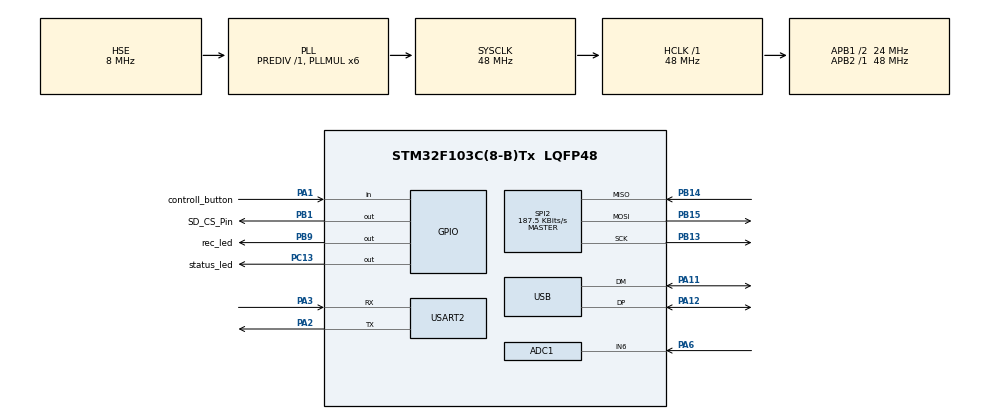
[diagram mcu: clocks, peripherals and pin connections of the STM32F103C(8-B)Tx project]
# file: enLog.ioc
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ADC1.Channel-5\#ChannelRegularConversion=ADC_CHANNEL_6
ADC1.NbrOfConversionFlag=1
ADC1.Rank-5\#ChannelRegularConversion=1
ADC1.SamplingTime-5\#ChannelRegularConversion=ADC_SAMPLETIME_1CYCLE_5
ADC1.master=1
Mcu.Family=STM32F1
Mcu.Name=STM32F103C(8-B)Tx
Mcu.Package=LQFP48
NVIC.PriorityGroup=NVIC_PRIORITYGROUP_4
NVIC.USB_LP_CAN1_RX0_IRQn=true\:0\:0\:false\:false\:true\:false\:true
PA1.GPIO_Label=controll_button
PA1.GPIO_PuPd=GPIO_PULLUP
PA1.Signal=GPIO_Input
PA11.Mode=Device
PA11.Signal=USB_DM
PA12.Mode=Device
PA12.Signal=USB_DP
PA13.Mode=Serial_Wire
PA13.Signal=SYS_JTMS-SWDIO
PA14.Mode=Serial_Wire
PA14.Signal=SYS_JTCK-SWCLK
PA2.Mode=Asynchronous
PA2.Signal=USART2_TX
PA3.Mode=Asynchronous
PA3.Signal=USART2_RX
PA6.Signal=ADCx_IN6
PB1.GPIO_Label=SD_CS_Pin
PB1.Signal=GPIO_Output
PB13.Mode=Full_Duplex_Master
PB13.Signal=SPI2_SCK
PB14.Mode=Full_Duplex_Master
PB14.Signal=SPI2_MISO
PB15.Mode=Full_Duplex_Master
PB15.Signal=SPI2_MOSI
PB9.GPIO_Label=rec_led
PB9.Signal=GPIO_Output
PC13-TAMPER-RTC.GPIO_Label=status_led
PC13-TAMPER-RTC.Signal=GPIO_Output
PC14-OSC32_IN.Mode=LSE-External-Oscillator
PC14-OSC32_IN.Signal=RCC_OSC32_IN
PC15-OSC32_OUT.Mode=LSE-External-Oscillator
PC15-OSC32_OUT.Signal=RCC_OSC32_OUT
PD0-OSC_IN.Mode=HSE-External-Oscillator
PD0-OSC_IN.Signal=RCC_OSC_IN
PD1-OSC_OUT.Mode=HSE-External-Oscillator
PD1-OSC_OUT.Signal=RCC_OSC_OUT
ProjectManager.HeapSize=0x200
ProjectManager.StackSize=0x400
ProjectManager.TargetToolchain=STM32CubeIDE
RCC.ADCPresc=RCC_ADCPCLK2_DIV4
RCC.AHBFreq_Value=48000000
RCC.APB1CLKDivider=RCC_HCLK_DIV2
RCC.APB1Freq_Value=24000000
RCC.APB1TimFreq_Value=48000000
RCC.APB2Freq_Value=48000000
RCC.APB2TimFreq_Value=48000000
RCC.HCLKFreq_Value=48000000
RCC.PLLMUL=RCC_PLL_MUL6
RCC.RTCClockSelection=RCC_RTCCLKSOURCE_LSE
RCC.SYSCLKFreq_VALUE=48000000
RCC.SYSCLKSource=RCC_SYSCLKSOURCE_PLLCLK
RCC.USBFreq_Value=48000000
SH.ADCx_IN6.0=ADC1_IN6,IN6
SPI2.BaudRatePrescaler=SPI_BAUDRATEPRESCALER_128
SPI2.CalculateBaudRate=187.5 KBits/s
SPI2.Direction=SPI_DIRECTION_2LINES
SPI2.Mode=SPI_MODE_MASTER
SPI2.VirtualType=VM_MASTER
USART2.VirtualMode=VM_ASYNC
USB_DEVICE.CLASS_NAME_FS=MSC
USB_DEVICE.VirtualMode=Msc
USB_DEVICE.VirtualModeFS=Msc_FS
VP_FATFS_VS_Generic.Mode=User_defined
VP_RTC_VS_RTC_Activate.Mode=RTC_Enabled
VP_RTC_VS_RTC_Calendar.Mode=RTC_Calendar
VP_USB_DEVICE_VS_USB_DEVICE_MSC_FS.Mode=MSC_FS
board=custom

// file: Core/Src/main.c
/* USER CODE BEGIN Header */
/**
  ******************************************************************************
  * @file           : main.c
  * @brief          : Main program body
  ******************************************************************************
  * @attention
  *
  * Copyright (c) 2021 STMicroelectronics.
  * All rights reserved.
  *
  * This software is licensed under terms that can be found in the LICENSE file
  * in the root directory of this software component.
  * If no LICENSE file comes with this software, it is provided AS-IS.
  *
  ******************************************************************************
  */
/* USER CODE END Header */
#include "main.h"
#include "fatfs.h"
#include "usb_device.h"

/* USER CODE BEGIN Includes */
#include <stdarg.h>
/* USER CODE END Includes */

ADC_HandleTypeDef hadc1;

RTC_HandleTypeDef hrtc;

SPI_HandleTypeDef hspi2;

UART_HandleTypeDef huart2;

void SystemClock_Config(void);
static void MX_GPIO_Init(void);
static void MX_ADC1_Init(void);
static void MX_RTC_Init(void);
static void MX_SPI2_Init(void);
static void MX_USART2_UART_Init(void);
/* USER CODE BEGIN PFP */
void UART_Printf(const char* fmt, ...);
/* USER CODE END PFP */

int main(void)
{

  /* MCU Configuration--------------------------------------------------------*/

  /* Reset of all peripherals, Initializes the Flash interface and the Systick. */
  HAL_Init();

  /* Configure the system clock */
  SystemClock_Config();

  /* Initialize all configured peripherals */
  MX_GPIO_Init();
  MX_ADC1_Init();
  MX_RTC_Init();
  MX_SPI2_Init();
  MX_USART2_UART_Init();
  MX_FATFS_Init();
  MX_USB_DEVICE_Init();

  /* Infinite loop */
  while (1)
  {

  }
}

void SystemClock_Config(void)
{
  RCC_OscInitTypeDef RCC_OscInitStruct = {0};
  RCC_ClkInitTypeDef RCC_ClkInitStruct = {0};
  RCC_PeriphCLKInitTypeDef PeriphClkInit = {0};

  /** Initializes the RCC Oscillators according to the specified parameters
  * in the RCC_OscInitTypeDef structure.
  */
  RCC_OscInitStruct.OscillatorType = RCC_OSCILLATORTYPE_HSE|RCC_OSCILLATORTYPE_LSE;
  RCC_OscInitStruct.HSEState = RCC_HSE_ON;
  RCC_OscInitStruct.HSEPredivValue = RCC_HSE_PREDIV_DIV1;
  RCC_OscInitStruct.LSEState = RCC_LSE_ON;
  RCC_OscInitStruct.HSIState = RCC_HSI_ON;
  RCC_OscInitStruct.PLL.PLLState = RCC_PLL_ON;
  RCC_OscInitStruct.PLL.PLLSource = RCC_PLLSOURCE_HSE;
  RCC_OscInitStruct.PLL.PLLMUL = RCC_PLL_MUL6;
  if (HAL_RCC_OscConfig(&RCC_OscInitStruct) != HAL_OK)
  {
    Error_Handler();
  }
  /** Initializes the CPU, AHB and APB buses clocks
  */
  RCC_ClkInitStruct.ClockType = RCC_CLOCKTYPE_HCLK|RCC_CLOCKTYPE_SYSCLK
                              |RCC_CLOCKTYPE_PCLK1|RCC_CLOCKTYPE_PCLK2;
  RCC_ClkInitStruct.SYSCLKSource = RCC_SYSCLKSOURCE_PLLCLK;
  RCC_ClkInitStruct.AHBCLKDivider = RCC_SYSCLK_DIV1;
  RCC_ClkInitStruct.APB1CLKDivider = RCC_HCLK_DIV2;
  RCC_ClkInitStruct.APB2CLKDivider = RCC_HCLK_DIV1;

  if (HAL_RCC_ClockConfig(&RCC_ClkInitStruct, FLASH_LATENCY_1) != HAL_OK)
  {
    Error_Handler();
  }
  PeriphClkInit.PeriphClockSelection = RCC_PERIPHCLK_RTC|RCC_PERIPHCLK_ADC
                              |RCC_PERIPHCLK_USB;
  PeriphClkInit.RTCClockSelection = RCC_RTCCLKSOURCE_LSE;
  PeriphClkInit.AdcClockSelection = RCC_ADCPCLK2_DIV4;
  PeriphClkInit.UsbClockSelection = RCC_USBCLKSOURCE_PLL;
  if (HAL_RCCEx_PeriphCLKConfig(&PeriphClkInit) != HAL_OK)
  {
    Error_Handler();
  }
}

static void MX_ADC1_Init(void)
{

  ADC_ChannelConfTypeDef sConfig = {0};

  /** Common config
  */
  hadc1.Instance = ADC1;
  hadc1.Init.ScanConvMode = ADC_SCAN_DISABLE;
  hadc1.Init.ContinuousConvMode = DISABLE;
  hadc1.Init.DiscontinuousConvMode = DISABLE;
  hadc1.Init.ExternalTrigConv = ADC_SOFTWARE_START;
  hadc1.Init.DataAlign = ADC_DATAALIGN_RIGHT;
  hadc1.Init.NbrOfConversion = 1;
  if (HAL_ADC_Init(&hadc1) != HAL_OK)
  {
    Error_Handler();
  }
  /** Configure Regular Channel
  */
  sConfig.Channel = ADC_CHANNEL_6;
  sConfig.Rank = ADC_REGULAR_RANK_1;
  sConfig.SamplingTime = ADC_SAMPLETIME_1CYCLE_5;
  if (HAL_ADC_ConfigChannel(&hadc1, &sConfig) != HAL_OK)
  {
    Error_Handler();
  }

}

static void MX_RTC_Init(void)
{

  RTC_TimeTypeDef sTime = {0};
  RTC_DateTypeDef DateToUpdate = {0};

  /** Initialize RTC Only
  */
  hrtc.Instance = RTC;
  hrtc.Init.AsynchPrediv = RTC_AUTO_1_SECOND;
  hrtc.Init.OutPut = RTC_OUTPUTSOURCE_ALARM;
  if (HAL_RTC_Init(&hrtc) != HAL_OK)
  {
    Error_Handler();
  }

  /** Initialize RTC and set the Time and Date
  */
  sTime.Hours = 0x0;
  sTime.Minutes = 0x0;
  sTime.Seconds = 0x0;

  if (HAL_RTC_SetTime(&hrtc, &sTime, RTC_FORMAT_BCD) != HAL_OK)
  {
    Error_Handler();
  }
  DateToUpdate.WeekDay = RTC_WEEKDAY_MONDAY;
  DateToUpdate.Month = RTC_MONTH_JANUARY;
  DateToUpdate.Date = 0x1;
  DateToUpdate.Year = 0x0;

  if (HAL_RTC_SetDate(&hrtc, &DateToUpdate, RTC_FORMAT_BCD) != HAL_OK)
  {
    Error_Handler();
  }

}

static void MX_SPI2_Init(void)
{

  /* SPI2 parameter configuration*/
  hspi2.Instance = SPI2;
  hspi2.Init.Mode = SPI_MODE_MASTER;
  hspi2.Init.Direction = SPI_DIRECTION_2LINES;
  hspi2.Init.DataSize = SPI_DATASIZE_8BIT;
  hspi2.Init.CLKPolarity = SPI_POLARITY_LOW;
  hspi2.Init.CLKPhase = SPI_PHASE_1EDGE;
  hspi2.Init.NSS = SPI_NSS_SOFT;
  hspi2.Init.BaudRatePrescaler = SPI_BAUDRATEPRESCALER_128;
  hspi2.Init.FirstBit = SPI_FIRSTBIT_MSB;
  hspi2.Init.TIMode = SPI_TIMODE_DISABLE;
  hspi2.Init.CRCCalculation = SPI_CRCCALCULATION_DISABLE;
  hspi2.Init.CRCPolynomial = 10;
  if (HAL_SPI_Init(&hspi2) != HAL_OK)
  {
    Error_Handler();
  }

}

static void MX_USART2_UART_Init(void)
{

  huart2.Instance = USART2;
  huart2.Init.BaudRate = 115200;
  huart2.Init.WordLength = UART_WORDLENGTH_8B;
  huart2.Init.StopBits = UART_STOPBITS_1;
  huart2.Init.Parity = UART_PARITY_NONE;
  huart2.Init.Mode = UART_MODE_TX_RX;
  huart2.Init.HwFlowCtl = UART_HWCONTROL_NONE;
  huart2.Init.OverSampling = UART_OVERSAMPLING_16;
  if (HAL_UART_Init(&huart2) != HAL_OK)
  {
    Error_Handler();
  }

}

static void MX_GPIO_Init(void)
{
  GPIO_InitTypeDef GPIO_InitStruct = {0};

  /* GPIO Ports Clock Enable */
  __HAL_RCC_GPIOC_CLK_ENABLE();
  __HAL_RCC_GPIOD_CLK_ENABLE();
  __HAL_RCC_GPIOA_CLK_ENABLE();
  __HAL_RCC_GPIOB_CLK_ENABLE();

  /*Configure GPIO pin Output Level */
  HAL_GPIO_WritePin(status_led_GPIO_Port, status_led_Pin, GPIO_PIN_RESET);

  /*Configure GPIO pin Output Level */
  HAL_GPIO_WritePin(GPIOB, SD_CS_Pin_Pin|rec_led_Pin, GPIO_PIN_RESET);

  /*Configure GPIO pin : status_led_Pin */
  GPIO_InitStruct.Pin = status_led_Pin;
  GPIO_InitStruct.Mode = GPIO_MODE_OUTPUT_PP;
  GPIO_InitStruct.Pull = GPIO_NOPULL;
  GPIO_InitStruct.Speed = GPIO_SPEED_FREQ_LOW;
  HAL_GPIO_Init(status_led_GPIO_Port, &GPIO_InitStruct);

  /*Configure GPIO pin : controll_button_Pin */
  GPIO_InitStruct.Pin = controll_button_Pin;
  GPIO_InitStruct.Mode = GPIO_MODE_INPUT;
  GPIO_InitStruct.Pull = GPIO_PULLUP;
  HAL_GPIO_Init(controll_button_GPIO_Port, &GPIO_InitStruct);

  /*Configure GPIO pins : SD_CS_Pin_Pin rec_led_Pin */
  GPIO_InitStruct.Pin = SD_CS_Pin_Pin|rec_led_Pin;
  GPIO_InitStruct.Mode = GPIO_MODE_OUTPUT_PP;
  GPIO_InitStruct.Pull = GPIO_NOPULL;
  GPIO_InitStruct.Speed = GPIO_SPEED_FREQ_LOW;
  HAL_GPIO_Init(GPIOB, &GPIO_InitStruct);

}

/* USER CODE BEGIN 4 */
void UART_Printf(const char* fmt, ...) {
    char buff[256];
    va_list args;
    va_start(args, fmt);
    vsnprintf(buff, sizeof(buff), fmt, args);
    HAL_UART_Transmit(&huart2, (uint8_t*)buff, strlen(buff),
                      HAL_MAX_DELAY);
    va_end(args);
}
/* USER CODE END 4 */

void Error_Handler(void)
{
  __disable_irq();
  while (1)
  {
  }
}
